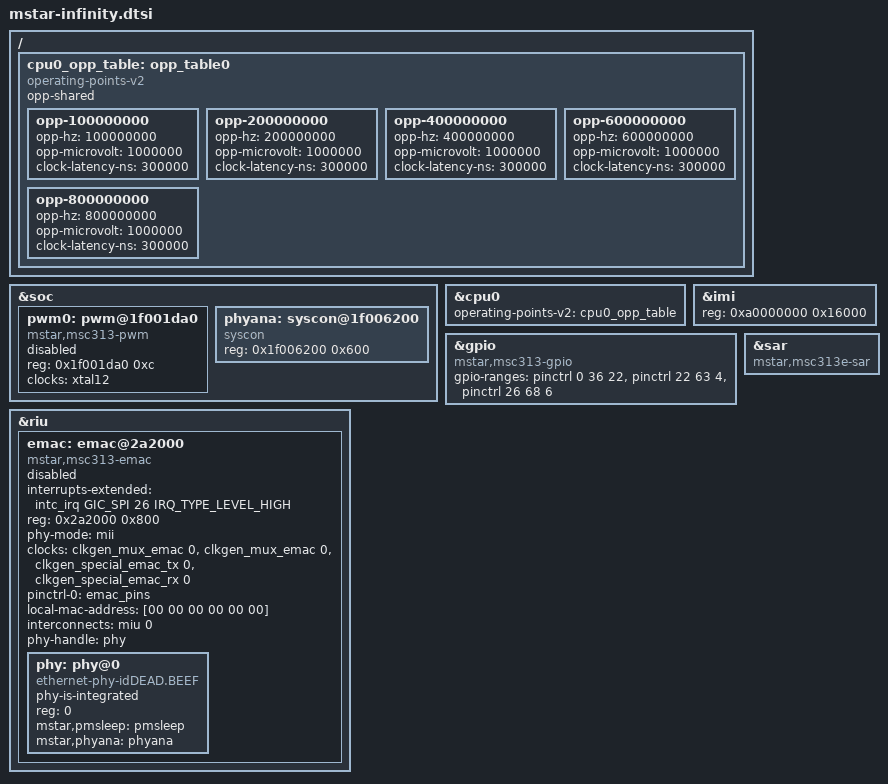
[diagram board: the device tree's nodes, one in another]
// SPDX-License-Identifier: GPL-2.0-or-later
/*
 * Copyright (c) 2020 thingy.jp.
 * Author: Daniel Palmer <daniel@thingy.jp>
 */

#include "mstar-v7.dtsi"

#include <dt-bindings/gpio/msc313-gpio.h>

/ {
	cpu0_opp_table: opp_table0 {
		compatible = "operating-points-v2";
		opp-shared;

		opp-100000000 {
			opp-hz = /bits/ 64 <100000000>;
			opp-microvolt = <1000000>;
			clock-latency-ns = <300000>;
		};

		opp-200000000 {
			opp-hz = /bits/ 64 <200000000>;
			opp-microvolt = <1000000>;
			clock-latency-ns = <300000>;
		};

		opp-400000000 {
			opp-hz = /bits/ 64 <400000000>;
			opp-microvolt = <1000000>;
			clock-latency-ns = <300000>;
		};
		opp-600000000 {
			opp-hz = /bits/ 64 <600000000>;
			opp-microvolt = <1000000>;
			clock-latency-ns = <300000>;
		};

		opp-800000000 {
			opp-hz = /bits/ 64 <800000000>;
			opp-microvolt = <1000000>;
			clock-latency-ns = <300000>;
		};
	};
};

&soc {
	pwm0: pwm@1f001da0 {
		compatible = "mstar,msc313-pwm";
		reg = <0x1f001da0 0xc>;
		#pwm-cells = <2>;
		clocks = <&xtal12>;
		status = "disabled";
	};

	phyana: syscon@1f006200 {
		/* albany ethernet phy
	         * 0x1f006200
		 * 0x1f006400
		 * 0x1f006600
		 */
		compatible = "syscon";
		reg = <0x1f006200 0x600>;
	};
};

&cpu0 {
	operating-points-v2 = <&cpu0_opp_table>;
};

&imi {
	reg = <0xa0000000 0x16000>;
};

&gpio {
	compatible = "mstar,msc313-gpio";
	gpio-ranges = <&pinctrl 0 36 22>,
		      <&pinctrl 22 63 4>,
		      <&pinctrl 26 68 6>;
	status = "okay";
};

&sar {
	compatible = "mstar,msc313e-sar";
};

&riu {
	emac: emac@2a2000 {
		#address-cells = <1>;
		#size-cells = <0>;
		compatible = "mstar,msc313-emac";
		interrupts-extended = <&intc_irq GIC_SPI 26 IRQ_TYPE_LEVEL_HIGH>;
		reg = <0x2a2000 0x800>;
		phy-mode = "mii";
		clock-names = "pclk", "hclk", "tx_clk", "rx_clk";
		clocks = <&clkgen_mux_emac 0>,
			 <&clkgen_mux_emac 0>,
			 <&clkgen_special_emac_tx 0>,
			 <&clkgen_special_emac_rx 0>;
		pinctrl-names = "default";
		pinctrl-0 = <&emac_pins>;
		local-mac-address = [00 00 00 00 00 00];
		status = "disabled";
		interconnects = <&miu 0>;
		interconnect-names = "dma-mem";
		phy-handle = <&phy>;
		phy: phy@0 {
			compatible = "ethernet-phy-idDEAD.BEEF";
			phy-is-integrated;
			reg = <0>;
			mstar,pmsleep = <&pmsleep>;
			mstar,phyana = <&phyana>;
		};
	};
};
